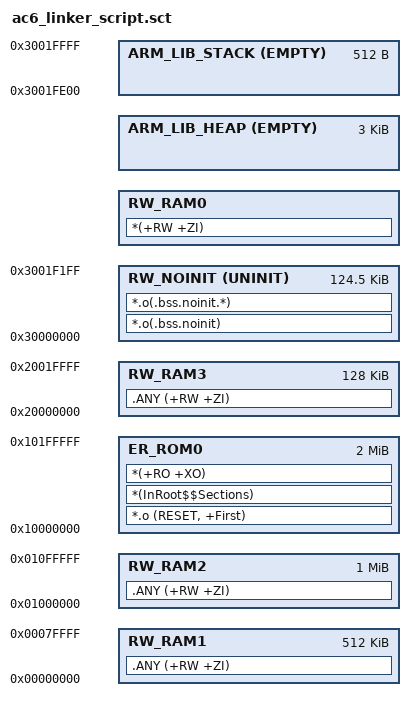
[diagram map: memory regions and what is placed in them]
# 1 "H:/AVH-Hello/RTE/Device/SSE-300-MPS3/ac6_linker_script.sct.src"
# 1 "<built-in>" 1
# 1 "<built-in>" 3
# 406 "<built-in>" 3
# 1 "<command line>" 1
# 1 "<built-in>" 2
# 1 "H:/AVH-Hello/RTE/Device/SSE-300-MPS3/regions_SSE-300-MPS3.h" 1
# 2 "<built-in>" 2
# 1 "H:/AVH-Hello/RTE/Device/SSE-300-MPS3/ac6_linker_script.sct.src" 2
# 32 "H:/AVH-Hello/RTE/Device/SSE-300-MPS3/ac6_linker_script.sct.src"
LR_ROM0 0x10000000 0x00200000 {

  ER_ROM0 0x10000000 0x00200000 {
    *.o (RESET, +First)
    *(InRoot$$Sections)
    *(+RO +XO)
  }







  RW_NOINIT 0x30000000 UNINIT (0x00020000 - 0x00000C00 - 0x00000200 - 0) {
    *.o(.bss.noinit)
    *.o(.bss.noinit.*)
  }

  RW_RAM0 AlignExpr(+0, 8) (0x00020000 - 0x00000C00 - 0x00000200 - 0 - AlignExpr(ImageLength(RW_NOINIT), 8)) {
    *(+RW +ZI)
  }


  ARM_LIB_HEAP (AlignExpr(+0, 8)) EMPTY 0x00000C00 { ; Reserve empty region for heap
  }


  ARM_LIB_STACK (0x30000000 + 0x00020000 - 0) EMPTY -0x00000200 { ; Reserve empty region for stack
  }







  RW_RAM1 0x00000000 0x00080000 {
   .ANY (+RW +ZI)
  }



  RW_RAM2 0x01000000 0x00100000 {
   .ANY (+RW +ZI)
  }



  RW_RAM3 0x20000000 0x00020000 {
   .ANY (+RW +ZI)
  }

}
